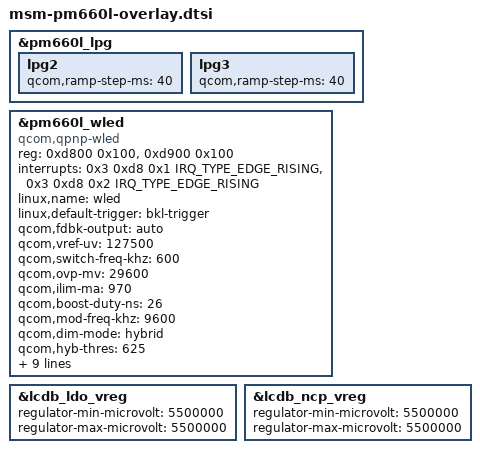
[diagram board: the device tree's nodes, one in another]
/* SPDX-License-Identifier: GPL-2.0 */

&pm660l_lpg {
    // Green
    lpg2 {
        qcom,ramp-step-ms = <40>;
    };

    // Red
    lpg3 {
        qcom,ramp-step-ms = <40>;
    };
};

&pm660l_wled {
    compatible = "qcom,qpnp-wled";
    reg = <0xd800 0x100>,
            <0xd900 0x100>;
    reg-names = "qpnp-wled-ctrl-base",
                   "qpnp-wled-sink-base";
    interrupts = <0x3 0xd8 0x1 IRQ_TYPE_EDGE_RISING>,
                    <0x3 0xd8 0x2 IRQ_TYPE_EDGE_RISING>;
    interrupt-names = "ovp-irq", "sc-irq";
    linux,name = "wled";
    linux,default-trigger = "bkl-trigger";
    qcom,fdbk-output = "auto";
    qcom,vref-uv = <127500>;
    qcom,switch-freq-khz = <600>;
    qcom,ovp-mv = <29600>;
    qcom,ilim-ma = <970>;
    qcom,boost-duty-ns = <26>;
    qcom,mod-freq-khz = <9600>;
    qcom,dim-mode = "hybrid";
    qcom,hyb-thres = <625>;
    qcom,sync-dly-us = <800>;
    qcom,fs-curr-ua = <20000>;
    qcom,cons-sync-write-delay-us = <1000>;
    qcom,led-strings-list = [00 01/* 02*/];
    qcom,en-ext-pfet-sc-pro;
    qcom,loop-auto-gm-en;
    qcom,pmic-revid = <&pm660l_revid>;
    qcom,en-cabc;
    qcom,auto-calibration-enable;
    status = "ok";
};

&lcdb_ldo_vreg {
	regulator-min-microvolt = <5500000>;
	regulator-max-microvolt = <5500000>;
};

&lcdb_ncp_vreg {
	regulator-min-microvolt = <5500000>;
	regulator-max-microvolt = <5500000>;
};
